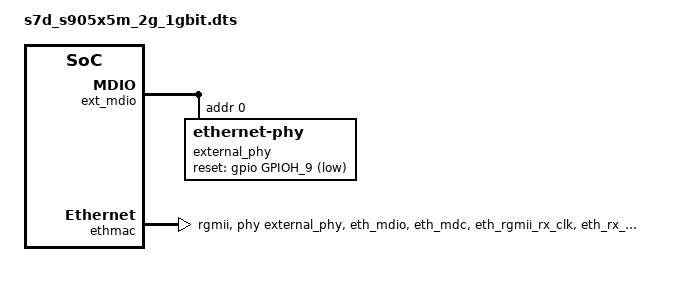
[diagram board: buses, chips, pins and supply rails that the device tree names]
#include "s7d_s905x5m_2g.dts"

/{
	coreelec-dt-id = "s7d_s905x5m_2g_1gbit";
};

&periphs_pinctrl {
	eth_pins_ext: eth-ext {
		mux {
			groups = "eth_mdio",
				 "eth_mdc",
				 "eth_rgmii_rx_clk",
				 "eth_rx_dv",
				 "eth_rxd0",
				 "eth_rxd1",
				 "eth_txen",
				 "eth_txd0",
				 "eth_txd1";
			function = "eth";
			drive-strength-microamp = <4000>;
			bias-disable;
		};
	};
};

&ext_mdio {
	external_phy: ethernet-phy@0 {
		reg = <0>;
		max-speed = <1000>;
		reset-assert-us = <10000>;
		reset-deassert-us = <80000>;
		reset-gpios = <&gpio GPIOH_9 (GPIO_ACTIVE_LOW | GPIO_OPEN_DRAIN)>;
	};
};

&ethmac {
	status = "okay";
	pinctrl-0 = <&eth_pins_ext>, <&eth_rgmii_pins>;
	pinctrl-names = "default";
	phy-mode = "rgmii";
	phy-handle = <&external_phy>;
	amlogic,tx-delay-ns = <2>;
	internal_phy = <0>;
};
